# PIC32CM1216MC00032 register map
Vendor: Microchip Technology; Series: PIC32CMMC00; File version: 0
CPU: CM0+ r0p0, little endian, MPU, no FPU, VTOR, 2 interrupt priority bits, 27 interrupts
Registers are 32-bit, read-write, reset 0x0 unless marked. A register's access mark holds for its fields unless they carry their own. Offsets are from the block's base; [hi:lo] are bit positions; {n}, {i} and the like mark numbered series; <NAME> marks a mode.

## ADC0 — Analog Digital Converter
Base 0x42004400; register names take the prefix ADC_
Same registers: ADC1 0x42004800
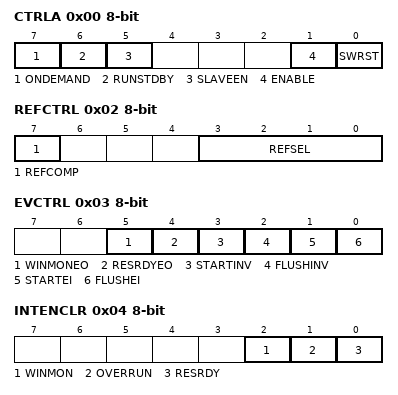
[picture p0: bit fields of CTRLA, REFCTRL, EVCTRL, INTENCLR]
0x00 CTRLA 8-bit — Control A
  [7] ONDEMAND — On Demand Control
  [6] RUNSTDBY — Run During Standby
  [5] SLAVEEN — Slave Enable
  [1] ENABLE
  [0] SWRST — Software Reset
0x01 CTRLB 8-bit — Control B
  [2:0] PRESCALER — Prescaler Configuration
    0=DIV2 (Peripheral clock divided by 2); 1=DIV4 (Peripheral clock divided by 4); 2=DIV8 (Peripheral clock divided by 8); 3=DIV16 (Peripheral clock divided by 16); 4=DIV32 (Peripheral clock divided by 32); 5=DIV64 (Peripheral clock divided by 64); 6=DIV128 (Peripheral clock divided by 128); 7=DIV256 (Peripheral clock divided by 256)
0x02 REFCTRL 8-bit — Reference Control
  [7] REFCOMP — Reference Buffer Offset Compensation Enable
  [3:0] REFSEL — Reference Selection
    0=INTREF (Internal Voltage Reference); 1=INTVCC0 (1/1.6 VDDANA); 2=INTVCC1 (1/2 VDDANA); 3=VREFA (External Voltage Reference A (shared with DAC)); 4=DAC (DAC Internal Output); 5=INTVCC2 (VDDANA)
0x03 EVCTRL 8-bit — Event Control
  [5] WINMONEO — Window Monitor Event Out
  [4] RESRDYEO — Result Ready Event Out
  [3] STARTINV — Start Event Invert Enable
  [2] FLUSHINV — Flush Event Invert Enable
  [1] STARTEI — Start Conversion Event Input Enable
  [0] FLUSHEI — Flush Event Input Enable
0x04 INTENCLR 8-bit write-1-clears — Interrupt Enable Clear
  [2] WINMON — Window Monitor Interrupt Disable
  [1] OVERRUN — Overrun Interrupt Disable
  [0] RESRDY — Result Ready Interrupt Disable
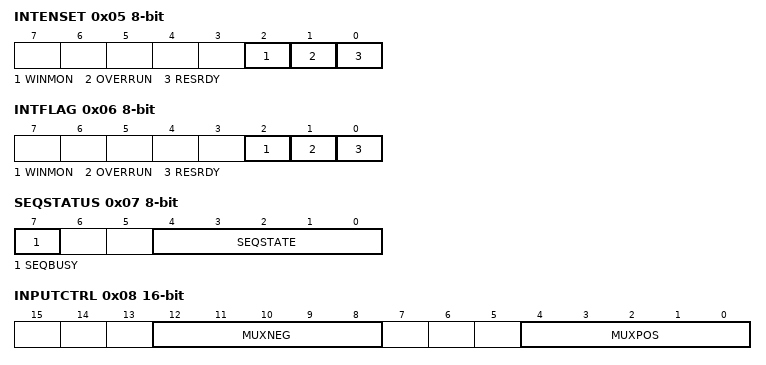
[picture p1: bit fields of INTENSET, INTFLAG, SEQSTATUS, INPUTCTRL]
0x05 INTENSET 8-bit write-1-sets — Interrupt Enable Set
  [2] WINMON — Window Monitor Interrupt Enable
  [1] OVERRUN — Overrun Interrupt Enable
  [0] RESRDY — Result Ready Interrupt Enable
0x06 INTFLAG 8-bit write-1-clears — Interrupt Flag Status and Clear
  [2] WINMON — Window Monitor Interrupt Flag
  [1] OVERRUN — Overrun Interrupt Flag
  [0] RESRDY — Result Ready Interrupt Flag
0x07 SEQSTATUS 8-bit ro — Sequence Status
  [7] SEQBUSY — Sequence Busy
  [4:0] SEQSTATE — Sequence State
0x08 INPUTCTRL 16-bit — Input Control
  [12:8] MUXNEG — Negative Mux Input Selection
    {v}=AIN{v} (ADC AIN{v} Pin) (v=0..5); 24=GND (Internal Ground)
  [4:0] MUXPOS — Positive Mux Input Selection
    {v}=AIN{v} (ADC AIN{v} Pin) (v=0..11); 25=INTREF (Internal Voltage Reference); 26=SCALEDVDDCORE (1/4 Scaled VDDCORE Supply); 27=SCALEDVDDANA (1/4 Scaled VDDANA Supply)
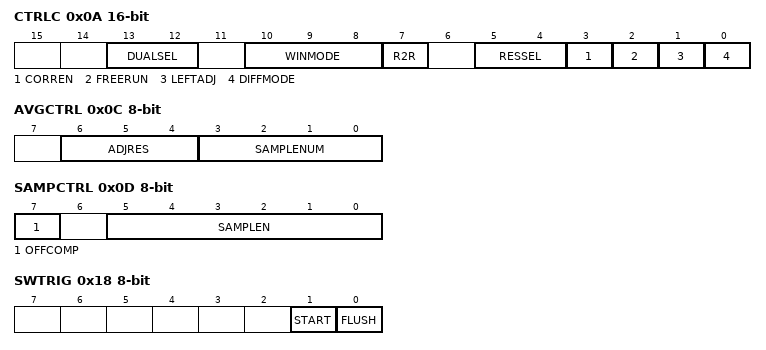
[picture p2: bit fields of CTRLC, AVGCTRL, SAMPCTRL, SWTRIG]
0x0A CTRLC 16-bit — Control C
  [13:12] DUALSEL — Dual Mode Trigger Selection
    0=BOTH (Start event or software trigger will start a conversion on both ADCs); 1=INTERLEAVE (START event or software trigger will alternatively start a conversion on ADC0 and ADC1)
  [10:8] WINMODE — Window Monitor Mode
    0=DISABLE (No window mode (default)); 1=MODE1 (RESULT > WINLT); 2=MODE2 (RESULT < WINUT); 3=MODE3 (WINLT < RESULT < WINUT); 4=MODE4 (!(WINLT < RESULT < WINUT))
  [7] R2R — Rail-to-Rail mode enable
  [5:4] RESSEL — Conversion Result Resolution
    0=12BIT (12-bit result); 1=16BIT (Accumulation or Oversampling and Decimation modes); 2=10BIT (10-bit result); 3=8BIT (8-bit result)
  [3] CORREN — Digital Correction Logic Enable
  [2] FREERUN — Free Running Mode
  [1] LEFTADJ — Left-Adjusted Result
  [0] DIFFMODE — Differential Mode
0x0C AVGCTRL 8-bit — Average Control
  [6:4] ADJRES — Adjusting Result / Division Coefficient
  [3:0] SAMPLENUM — Number of Samples to be Collected
    0=1 sample; 1=2 samples; 2=4 samples; 3=8 samples; 4=16 samples; 5=32 samples; 6=64 samples; 7=128 samples; 8=256 samples; 9=512 samples; 10=1024 samples
0x0D SAMPCTRL 8-bit — Sample Time Control
  [7] OFFCOMP — Comparator Offset Compensation Enable
  [5:0] SAMPLEN — Sampling Time Length
0x0E WINLT 16-bit — Window Monitor Lower Threshold
  [15:0] WINLT — Window Lower Threshold
0x10 WINUT 16-bit — Window Monitor Upper Threshold
  [15:0] WINUT — Window Upper Threshold
0x12 GAINCORR 16-bit — Gain Correction
  [11:0] GAINCORR — Gain Correction Value
0x14 OFFSETCORR 16-bit — Offset Correction
  [11:0] OFFSETCORR — Offset Correction Value
0x18 SWTRIG 8-bit — Software Trigger
  [1] START — Start ADC Conversion
  [0] FLUSH — ADC Flush
0x1C DBGCTRL 8-bit — Debug Control
  [0] DBGRUN — Debug Run
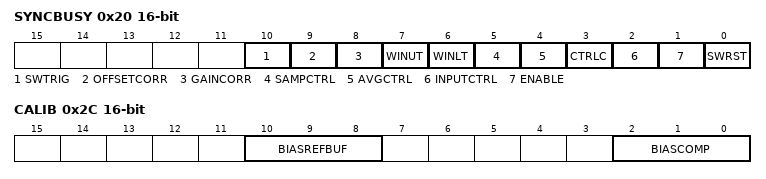
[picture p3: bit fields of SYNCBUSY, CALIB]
0x20 SYNCBUSY 16-bit ro — Synchronization Busy
  [10] SWTRIG — SWTRG Synchronization Busy
  [9] OFFSETCORR — OFFSETCTRL Synchronization Busy
  [8] GAINCORR — GAINCORR Synchronization Busy
  [7] WINUT — WINUT Synchronization Busy
  [6] WINLT — WINLT Synchronization Busy
  [5] SAMPCTRL — SAMPCTRL Synchronization Busy
  [4] AVGCTRL — AVGCTRL Synchronization Busy
  [3] CTRLC — CTRLC Synchronization Busy
  [2] INPUTCTRL — INPUTCTRL Synchronization Busy
  [1] ENABLE — ENABLE Synchronization Busy
  [0] SWRST — SWRST Synchronization Busy
0x24 RESULT 16-bit ro
  [15:0] RESULT — Result Value
0x28 SEQCTRL — Sequence Control
  [31:0] SEQEN — Enable Positive Input in the Sequence
0x2C CALIB 16-bit — Calibration
  [10:8] BIASREFBUF — Bias Reference Buffer Scaling
  [2:0] BIASCOMP — Bias Comparator Scaling

## Notices in the file
Copyright (c) 2026 Microchip Technology Inc.
SPDX-License-Identifier: Apache-2.0
Licensed under the Apache License, Version 2.0 (the "License");
you may not use this file except in compliance with the License.
You may obtain a copy of the License at
http://www.apache.org/licenses/LICENSE-2.0
Unless required by applicable law or agreed to in writing, software
distributed under the License is distributed on an "AS IS" BASIS,
WITHOUT WARRANTIES OR CONDITIONS OF ANY KIND, either express or implied.
See the License for the specific language governing permissions and
limitations under the License.
